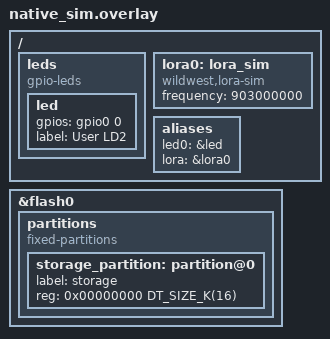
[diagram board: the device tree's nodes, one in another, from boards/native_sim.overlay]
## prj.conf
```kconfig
# Copyright (c) 2024 Aaron Chan
# SPDX-License-Identifier: Apache-2.0
CONFIG_LORA=y
CONFIG_LOG=y
CONFIG_CBPRINTF_FP_SUPPORT=y

CONFIG_UART_INTERRUPT_DRIVEN=y
CONFIG_CONSOLE=y
CONFIG_PRINTK=y
CONFIG_UART_CONSOLE=y
CONFIG_LOG_BACKEND_UART=y
CONFIG_SERIAL=y
CONFIG_LOG_MODE_IMMEDIATE=y
CONFIG_LOG_MODE_DEFERRED=n
#CONFIG_LORA_LOG_LEVEL_DBG=y
CONFIG_LORA_LOG_LEVEL_ERR=y
CONFIG_CPP=y
CONFIG_REQUIRES_FULL_LIBCPP=y
CONFIG_STD_CPP23=y

CONFIG_MAIN_STACK_SIZE=2048

# Need more memory :(
CONFIG_SHELL=y
CONFIG_SHELL_LOG_BACKEND=n

CONFIG_FLASH=y
CONFIG_FLASH_MAP=y
CONFIG_NVS=y
CONFIG_SETTINGS=y
CONFIG_SETTINGS_NVS=y
CONFIG_MPU_ALLOW_FLASH_WRITE=y

CONFIG_WATCHDOG=y
CONFIG_HWINFO=y


# Core
CONFIG_CORE=y
CONFIG_CORE_GNSS=y
CONFIG_CORE_SETTINGS=y
CONFIG_CORE_LORA=y
CONFIG_CORE_TDMA_TIME=y
#CONFIG_LORA_LOG_LEVEL_DBG=y

# Core Settings
CONFIG_SHELL_FREQUENCY=y
```

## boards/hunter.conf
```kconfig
# Keep legacy Hunter within the STM32F030 flash/RAM budget.
CONFIG_SHELL=n
```

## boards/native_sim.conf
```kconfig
# Disable real SPI hardware but keep LoRa enabled via sim
CONFIG_SPI=n
CONFIG_LORA=y
CONFIG_LORA_SIM=y

# Console on native stdin/stdout
CONFIG_SERIAL=y
CONFIG_CONSOLE=y
CONFIG_NATIVE_UART_0_ON_STDINOUT=y

# NVS on emulated flash
CONFIG_FLASH=y
CONFIG_FLASH_MAP=y
CONFIG_NVS=y

# GPIO for LED stub
CONFIG_GPIO=y
```

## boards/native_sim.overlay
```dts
/ {
	leds: leds {
		compatible = "gpio-leds";

		led: led {
			gpios = <&gpio0 0 GPIO_ACTIVE_HIGH>;
			label = "User LD2";
		};
	};

	// Simulated LoRa over UDP multicast
	lora0: lora_sim {
		compatible = "wildwest,lora-sim";
		frequency = <903000000>;
		status = "okay";
	};

	aliases {
		led0 = &led;
		lora = &lora0;
	};
};

&flash0 {
	partitions {
		compatible = "fixed-partitions";
		#address-cells = <1>;
		#size-cells = <1>;

		storage_partition: partition@0 {
			label = "storage";
			reg = <0x00000000 DT_SIZE_K(16)>;
		};
	};
};
```

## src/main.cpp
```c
/*
 * Copyright (c) 2024 Aaron Chan
 * SPDX-License-Identifier: Apache-2.0
 */

#include "core/LoraTransceiver.h"
#include "core/Settings.h"

#include <zephyr/device.h>
#include <zephyr/drivers/watchdog.h>
#include <zephyr/kernel.h>
#include <zephyr/logging/log.h>
#include <zephyr/logging/log_ctrl.h>

LOG_MODULE_REGISTER(main);

int main(void) {
    const int ret = Settings::load();
    if (ret != 0) {
        LOG_ERR("Settings::load failed: %d", ret);
    }

    const uint32_t freqHz = Settings::getFrequency();
    const float freqMhz = static_cast<float>(freqHz) / 1'000'000.0f;
    LoraTransceiver lora(0, freqMhz);
    lora.awaitRxPacket();

    const device *wdt = DEVICE_DT_GET(DT_ALIAS(watchdog0));
    int wdt_channel_id = -1;
    if (!device_is_ready(wdt)) {
        LOG_ERR("Watchdog device not ready");
    } else {
        wdt_timeout_cfg wdt_cfg{};
        wdt_cfg.window.min = 0U;
        wdt_cfg.window.max = 60'000U;
        wdt_cfg.callback = nullptr;
        wdt_cfg.flags = WDT_FLAG_RESET_SOC;
        wdt_channel_id = wdt_install_timeout(wdt, &wdt_cfg);
        if (wdt_channel_id < 0) {
            LOG_ERR("wdt_install_timeout failed: %d", wdt_channel_id);
        } else if (wdt_setup(wdt, 0) != 0) {
            LOG_ERR("wdt_setup failed");
            wdt_channel_id = -1;
        }
    }

    while (true) {
        if (wdt_channel_id >= 0) {
            wdt_feed(wdt, wdt_channel_id);
        }
        k_sleep(K_SECONDS(30));
        lora.awaitCancel();
        lora.awaitRxPacket();
    }

    return 0;
}
```
